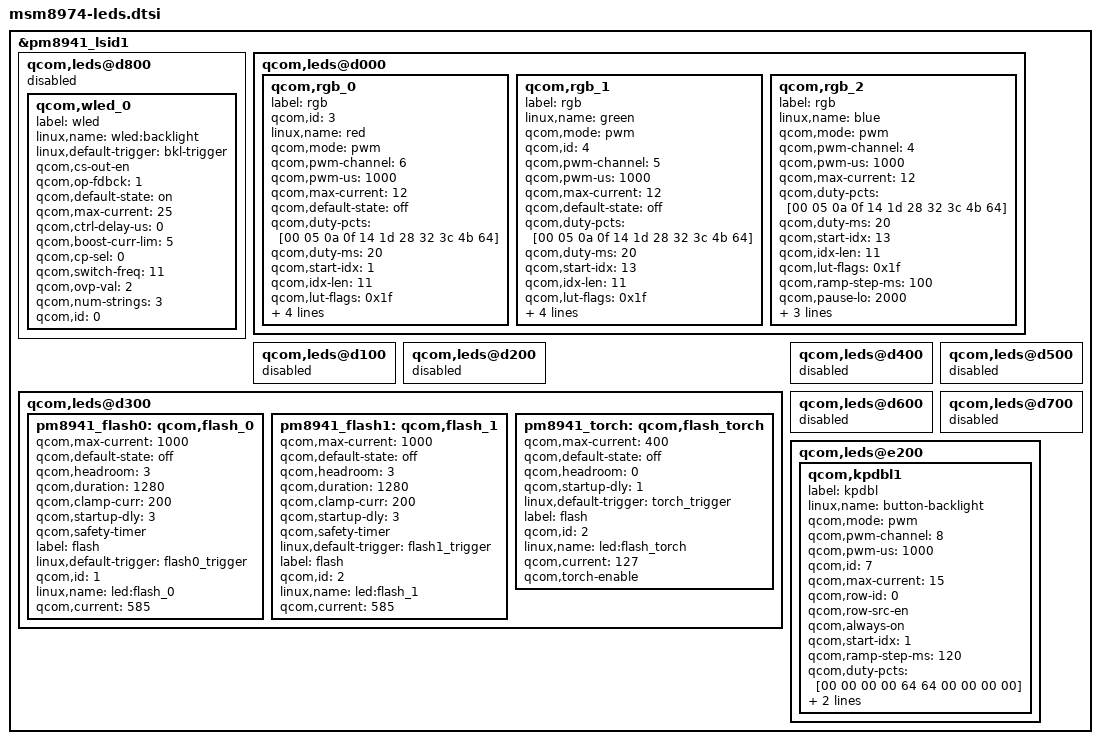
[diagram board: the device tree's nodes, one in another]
/*
 * Copyright (c) 2012-2013, The Linux Foundation. All rights reserved.
 *
 * This program is free software; you can redistribute it and/or modify
 * it under the terms of the GNU General Public License version 2 and
 * only version 2 as published by the Free Software Foundation.
 *
 * This program is distributed in the hope that it will be useful,
 * but WITHOUT ANY WARRANTY; without even the implied warranty of
 * MERCHANTABILITY or FITNESS FOR A PARTICULAR PURPOSE.  See the
 * GNU General Public License for more details.
 */

&pm8941_lsid1 {

	qcom,leds@d800 {
		status = "disabled";
		qcom,wled_0 {
			label = "wled";
			linux,name = "wled:backlight";
			linux,default-trigger = "bkl-trigger";
			qcom,cs-out-en;
			qcom,op-fdbck = <1>;
			qcom,default-state = "on";
			qcom,max-current = <25>;
			qcom,ctrl-delay-us = <0>;
			qcom,boost-curr-lim = <5>;
			qcom,cp-sel = <0>;
			qcom,switch-freq = <11>;
			qcom,ovp-val = <2>;
			qcom,num-strings = <3>;
			qcom,id = <0>;
		};
	};

	qcom,leds@d000 {
		status = "okay";
		qcom,rgb_0 {
			label = "rgb";
			qcom,id = <3>;
			linux,name = "red";
			qcom,mode = "pwm";
			qcom,pwm-channel = <6>;
			qcom,pwm-us = <1000>;
			qcom,max-current = <12>;
			qcom,default-state = "off";
			qcom,duty-pcts = [00 05 0a 0f 14 1d 28 32 3c 4b 64];
			qcom,duty-ms = <20>;
			qcom,start-idx = <1>;
			qcom,idx-len = <11>;

				qcom,lut-flags = <0x1f>;
				qcom,ramp-step-ms = <100>;
				qcom,pause-lo = <2000>;
				qcom,pause-hi = <1000>;
			/*linux,default-trigger =
				"battery-charging";
				*/
			qcom,use-blink;
		};

		qcom,rgb_1 {
			label = "rgb";
			linux,name = "green";
			qcom,mode = "pwm";
			qcom,id = <4>;
			qcom,pwm-channel = <5>;
			qcom,pwm-us = <1000>;
			qcom,max-current = <12>;
			qcom,default-state = "off";
				qcom,duty-pcts = [00 05 0a 0f 14 1d 28 32 3c 4b 64];
				qcom,duty-ms = <20>;
				qcom,start-idx = <13>;
				qcom,idx-len = <11>;


			qcom,lut-flags = <0x1f>;
			qcom,ramp-step-ms = <100>;
			qcom,pause-lo = <2000>;
			qcom,pause-hi = <1000>;

			//linux,default-trigger = "battery-full";
			qcom,use-blink;
		};

		qcom,rgb_2 {
			label = "rgb";
			linux,name = "blue";
			qcom,mode = "pwm";
			qcom,pwm-channel = <4>;
			qcom,pwm-us = <1000>;
			qcom,max-current = <12>;

				qcom,duty-pcts = [00 05 0a 0f 14 1d 28 32 3c 4b 64];
				qcom,duty-ms = <20>;
				qcom,start-idx = <13>;
				qcom,idx-len = <11>;

				qcom,lut-flags = <0x1f>;
				qcom,ramp-step-ms = <100>;
				qcom,pause-lo = <2000>;
				qcom,pause-hi = <1000>;

			qcom,id = <5>;
			qcom,use-blink;
		};
	};

	qcom,leds@d100 {
		status = "disabled";
	};

	qcom,leds@d200 {
		status = "disabled";
	};

	qcom,leds@d300 {
		status = "okay";
		pm8941_flash0: qcom,flash_0 {
			qcom,max-current = <1000>;
			qcom,default-state = "off";
			qcom,headroom = <3>;
			qcom,duration = <1280>;
			qcom,clamp-curr = <200>;
			qcom,startup-dly = <3>;
			qcom,safety-timer;
			label = "flash";
			linux,default-trigger =
				"flash0_trigger";
			qcom,id = <1>;
			linux,name = "led:flash_0";
			qcom,current = <585>;
		};

		pm8941_flash1: qcom,flash_1 {
			qcom,max-current = <1000>;
			qcom,default-state = "off";
			qcom,headroom = <3>;
			qcom,duration = <1280>;
			qcom,clamp-curr = <200>;
			qcom,startup-dly = <3>;
			qcom,safety-timer;
			linux,default-trigger =
				"flash1_trigger";
			label = "flash";
			qcom,id = <2>;
			linux,name = "led:flash_1";
			qcom,current = <585>;
		};

		pm8941_torch: qcom,flash_torch {
			qcom,max-current = <400>;
			qcom,default-state = "off";
			qcom,headroom = <0>;
			qcom,startup-dly = <1>;
			linux,default-trigger =
				"torch_trigger";
			label = "flash";
			qcom,id = <2>;
			linux,name = "led:flash_torch";
			qcom,current = <127>;
			qcom,torch-enable;
		};
	};

	qcom,leds@d400 {
		status = "disabled";
	};

	qcom,leds@d500 {
		status = "disabled";
	};

	qcom,leds@d600 {
		status = "disabled";
	};

	qcom,leds@d700 {
		status = "disabled";
	};
/*VENDOR_EDIT*/
/*OPPO yuyi 2013-09-27 modify begin for button-backlight*/		
	qcom,leds@e200 {
		status = "okay";

		qcom,kpdbl1 {
			label = "kpdbl";
			linux,name = "button-backlight";
			qcom,mode = "pwm";
			qcom,pwm-channel = <8>;
			qcom,pwm-us = <1000>;
			qcom,id = <7>;
			/*OPPO yuyi 2013-11-26 modify current for button-backlight*/
			/*qcom,max-current = <20>;*/
			qcom,max-current = <15>;
			/*OPPO yuyi 2013-11-26 modify end for button-backlight*/
			qcom,row-id = <0>;
			qcom,row-src-en;
			qcom,always-on;
			qcom,start-idx = <1>;
			qcom,ramp-step-ms = <120>;
			qcom,duty-pcts = [00 00 00 00 64
					64 00 00 00 00];
			qcom,use-blink;
			qcom,in-order-command-processing;
		};
/*OPPO yuyi 2013-09-27 modify end for button-backlight*/
/*
		qcom,kpdbl2 {
			label = "kpdbl";
			linux,name = "kpdbl-pwm-2";
			qcom,mode = "pwm";
			qcom,pwm-channel = <9>;
			qcom,pwm-us = <1000>;
			qcom,id = <7>;
			qcom,max-current = <20>;
			qcom,row-id = <1>;
			qcom,row-src-en;
                        qcom,start-idx = <1>;
                        qcom,ramp-step-ms = <120>;
                        qcom,duty-pcts = [00 00 00 00 64
                                        64 00 00 00 00];
                        qcom,use-blink;
                        qcom,in-order-command-processing;

		};

		qcom,kpdbl3 {
			label = "kpdbl";
			linux,name = "kpdbl-pwm-3";
			qcom,mode = "pwm";
			qcom,pwm-channel = <10>;
			qcom,pwm-us = <1000>;
			qcom,id = <7>;
			qcom,max-current = <20>;
			qcom,row-id = <2>;
			qcom,row-src-en;
                        qcom,start-idx = <1>;
                        qcom,ramp-step-ms = <120>;
                        qcom,duty-pcts = [00 00 00 00 64
                                        64 00 00 00 00];
                        qcom,use-blink;
                        qcom,in-order-command-processing;

		};

		qcom,kpdbl4 {
			label = "kpdbl";
			linux,name = "kpdbl-pwm-4";
			qcom,mode = "pwm";
			qcom,pwm-channel = <11>;
			qcom,pwm-us = <1000>;
			qcom,id = <7>;
			qcom,max-current = <20>;
			qcom,row-id = <3>;
			qcom,row-src-en;
                        qcom,start-idx = <1>;
                        qcom,ramp-step-ms = <120>;
                        qcom,duty-pcts = [00 00 00 00 64
                                        64 00 00 00 00];
                        qcom,use-blink;
                        qcom,in-order-command-processing;

		};
		*/
	};
};
